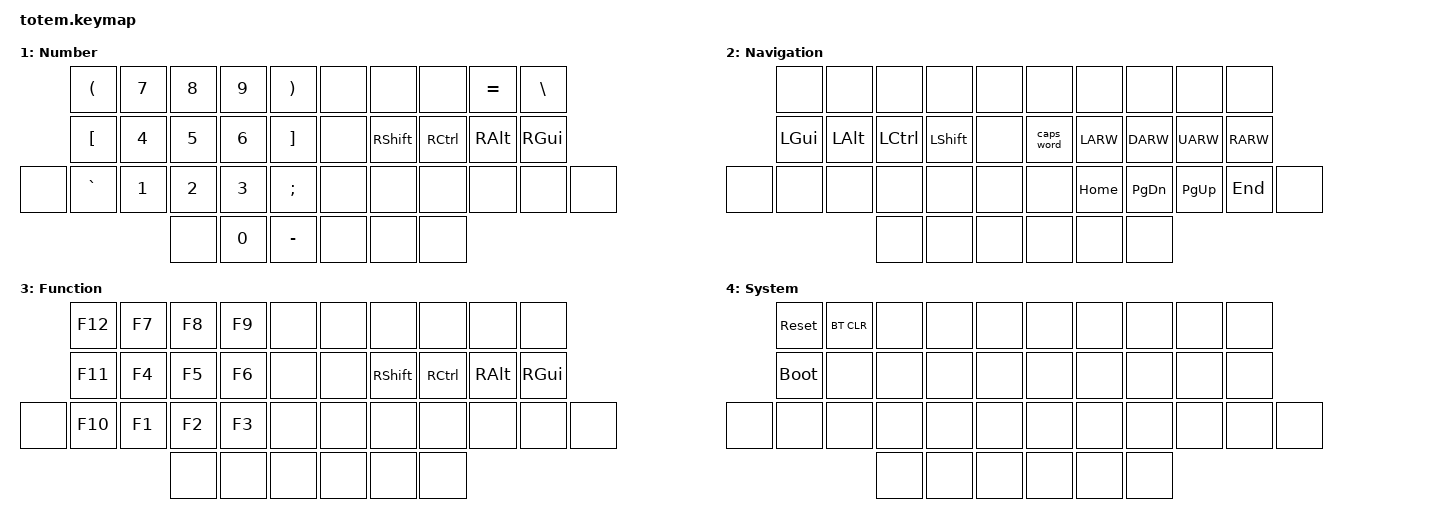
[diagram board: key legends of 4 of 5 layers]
//
//                                                        ▀▀▀▀▀     ▀▀▀▀▀          ▀▀█▀▀
//                                                        ▄▀▀▀▄  ▄  ▄▀▀▀▄  ▄  ▄▀▀▀▄  █  ▄▀▀▀▄
//                                                        █   █  █  █   █  █  █   █  █  █   █
//                                                         ▀▀▀   █   ▀▀▀   █   ▀▀▀   ▀   ▀▀▀
//                                                               █      ▄▄▄█▄▄▄    █   █  
//                                                               ▀      █  █  █     █▄█
//                                                             ▀▀▀▀▀    █  █  █      ▀
//                                                                      ▀  ▀  ▀
//
// ▄▄▄▄▄▄▄▄▄▄▄▄▄▄▄▄▄▄▄▄▄▄▄▄▄▄▄▄▄▄▄▄▄▄▄▄▄▄▄▄▄▄▄▄▄▄▄▄▄▄▄▄▄▄▄▄▄▄▄▄▄▄▄▄▄▄▄▄▄▄▄▄▄▄▄▄▄▄▄▄▄▄▄▄▄▄▄▄▄▄▄▄▄▄▄▄▄▄▄▄▄▄▄▄▄▄▄▄▄▄▄▄▄▄▄▄▄▄▄▄▄▄▄▄▄▄▄▄▄▄▄▄▄▄▄▄▄▄▄▄▄▄▄▄▄▄▄▄▄
       

#include <behaviors.dtsi>
#include <dt-bindings/zmk/keys.h>
#include <dt-bindings/zmk/bt.h>

#define BASE 0
#define NUM  1
#define NAV  2
#define FUNC 3
#define SYS  4

// Home row mods macro
#define GACS(k1,k2,k3,k4)   &hm LGUI k1     &hm LALT k2     &hm LCTRL k3    &hm LSHFT k4
#define SCAG(k1,k2,k3,k4)   &hm RSHFT k1    &hm RCTRL k2    &hm RALT k3     &hm RGUI k4

/ {
    behaviors {
        hm: homerow_mods {
            compatible = "zmk,behavior-hold-tap";
            label = "HOMEROW_MODS";
            #binding-cells = <2>;
            tapping-term-ms = <170>;
            quick-tap-ms = <0>;
            flavor = "tap-preferred";
            bindings = <&kp>, <&kp>;
        };
    };


    keymap {
        compatible = "zmk,keymap";
// ▄▄▄▄▄▄▄▄▄▄▄▄▄▄▄▄▄▄▄▄▄▄▄▄▄▄▄▄▄▄▄▄▄▄▄▄▄▄▄▄▄▄▄▄▄▄▄▄▄▄▄▄▄▄▄▄▄▄▄▄▄▄▄▄▄▄▄▄▄▄▄▄▄▄▄▄▄▄▄▄▄▄▄▄▄▄▄▄▄▄▄▄▄▄▄▄▄▄▄▄▄▄▄▄▄▄▄▄▄▄▄▄▄▄▄▄▄▄▄▄▄▄▄▄▄▄▄▄▄▄▄▄▄▄▄▄▄▄▄▄▄▄▄▄▄▄▄▄▄

        base_layer {
// ┏━━━━━━━━━━━━━━━━━━━━━━━━━━━━━━━━━━━━━━━┓
label= "BASE"                              ;
display-name= "Base"                       ;
// ┗━━━━━━━━━━━━━━━━━━━━━━━━━━━━━━━━━━━━━━━┛
//             ┏━━━━━━━━━━━┳━━━━━━━━━━━┳━━━━━━━━━━━┳━━━━━━━━━━━┳━━━━━━━━━━━┓   ┏━━━━━━━━━━━┳━━━━━━━━━━━┳━━━━━━━━━━━┳━━━━━━━━━━━┳━━━━━━━━━━━┓
//             ┃     Q     ┃     W     ┃     F     ┃     P     ┃     B     ┃   ┃     J     ┃     L     ┃     U     ┃     Y     ┃     '     ┃
//             ┣━━━━━━━━━━━╋━━━━━━━━━━━╋━━━━━━━━━━━╋━━━━━━━━━━━╋━━━━━━━━━━━┫   ┣━━━━━━━━━━━╋━━━━━━━━━━━╋━━━━━━━━━━━╋━━━━━━━━━━━╋━━━━━━━━━━━┫
//             ┃     A     ┃     R     ┃     S     ┃     T     ┃     G     ┃   ┃     M     ┃     N     ┃     E     ┃     I     ┃     O     ┃
// ┏━━━━━━━━━━━╋━━━━━━━━━━━╋━━━━━━━━━━━╋━━━━━━━━━━━╋━━━━━━━━━━━╋━━━━━━━━━━━┫   ┣━━━━━━━━━━━╋━━━━━━━━━━━╋━━━━━━━━━━━╋━━━━━━━━━━━╋━━━━━━━━━━━╋━━━━━━━━━━━┓
// ┃           ┃     Z     ┃     X     ┃     C     ┃     D     ┃     V     ┃   ┃     K     ┃     H     ┃     ,     ┃     .     ┃     /     ┃           ┃
// ┗━━━━━━━━━━━┻━━━━━━━━━━━┻━━━━━━━━━━━╋━━━━━━━━━━━╋━━━━━━━━━━━╋━━━━━━━━━━━┫   ┣━━━━━━━━━━━╋━━━━━━━━━━━╋━━━━━━━━━━━╋━━━━━━━━━━━┻━━━━━━━━━━━┻━━━━━━━━━━━┛
//                                     ┃    ESC    ┃    SPC    ┃    TAB    ┃   ┃   ENTER   ┃   BSPC    ┃    DEL    ┃
//                                     ┗━━━━━━━━━━━┻━━━━━━━━━━━┻━━━━━━━━━━━┛   ┗━━━━━━━━━━━┻━━━━━━━━━━━┻━━━━━━━━━━━┛
            bindings = <
// ╷           ╷           ╷           ╷           ╷           ╷           ╷   ╷           ╷           ╷           ╷           ╷           ╷           ╷

                &kp Q       &kp W       &kp F       &kp P       &kp B           &kp J       &kp L       &kp U       &kp Y       &kp SQT
                GACS(A,     R,          S,          T)          &kp G           &kp M       SCAG(N,     E,          I,          O)
    &kp Z       &kp Z       &kp X       &kp C       &kp D       &kp V           &kp K       &kp H       &kp COMMA   &kp DOT     &kp FSLH    &kp FSLH
                                        &kp ESC     &lt NAV SPACE &lt SYS TAB   &lt FUNC RET &lt NUM BSPC    &kp DEL
            >;
        };

// ▄▄▄▄▄▄▄▄▄▄▄▄▄▄▄▄▄▄▄▄▄▄▄▄▄▄▄▄▄▄▄▄▄▄▄▄▄▄▄▄▄▄▄▄▄▄▄▄▄▄▄▄▄▄▄▄▄▄▄▄▄▄▄▄▄▄▄▄▄▄▄▄▄▄▄▄▄▄▄▄▄▄▄▄▄▄▄▄▄▄▄▄▄▄▄▄▄▄▄▄▄▄▄▄▄▄▄▄▄▄▄▄▄▄▄▄▄▄▄▄▄▄▄▄▄▄▄▄▄▄▄▄▄▄▄▄▄▄▄▄▄▄▄▄▄▄▄▄▄


        number_layer {
// ┏━━━━━━━━━━━━━━━━━━━━━━━━━━━━━━━━━━━━━━━┓
label= "NUM"                               ;
display-name= "Number"                     ;
// ┗━━━━━━━━━━━━━━━━━━━━━━━━━━━━━━━━━━━━━━━┛
//             ┏━━━━━━━━━━━┳━━━━━━━━━━━┳━━━━━━━━━━━┳━━━━━━━━━━━┳━━━━━━━━━━━┓   ┏━━━━━━━━━━━┳━━━━━━━━━━━┳━━━━━━━━━━━┳━━━━━━━━━━━┳━━━━━━━━━━━┓
//             ┃     (     ┃     7     ┃     8     ┃     9     ┃     )     ┃   ┃           ┃           ┃           ┃     =     ┃     \     ┃
//             ┣━━━━━━━━━━━╋━━━━━━━━━━━╋━━━━━━━━━━━╋━━━━━━━━━━━╋━━━━━━━━━━━┫   ┣━━━━━━━━━━━╋━━━━━━━━━━━╋━━━━━━━━━━━╋━━━━━━━━━━━╋━━━━━━━━━━━┫
//             ┃     [     ┃     4     ┃     5     ┃     6     ┃     ]     ┃   ┃           ┃   RSHFT   ┃   RCTRL   ┃   RALT    ┃   RGUI    ┃
// ┏━━━━━━━━━━━╋━━━━━━━━━━━╋━━━━━━━━━━━╋━━━━━━━━━━━╋━━━━━━━━━━━╋━━━━━━━━━━━┫   ┣━━━━━━━━━━━╋━━━━━━━━━━━╋━━━━━━━━━━━╋━━━━━━━━━━━╋━━━━━━━━━━━╋━━━━━━━━━━━┓
// ┃           ┃     `     ┃     1     ┃     2     ┃     3     ┃     ;     ┃   ┃           ┃           ┃           ┃           ┃           ┃           ┃
// ┗━━━━━━━━━━━┻━━━━━━━━━━━┻━━━━━━━━━━━╋━━━━━━━━━━━╋━━━━━━━━━━━╋━━━━━━━━━━━┫   ┣━━━━━━━━━━━╋━━━━━━━━━━━╋━━━━━━━━━━━╋━━━━━━━━━━━┻━━━━━━━━━━━┻━━━━━━━━━━━┛
//                                     ┃           ┃     0     ┃     -     ┃   ┃           ┃           ┃           ┃
//                                     ┗━━━━━━━━━━━┻━━━━━━━━━━━┻━━━━━━━━━━━┛   ┗━━━━━━━━━━━┻━━━━━━━━━━━┻━━━━━━━━━━━┛
            bindings = <
// ╷           ╷           ╷           ╷           ╷           ╷           ╷   ╷           ╷           ╷           ╷           ╷           ╷           ╷

                &kp LPAR    &kp N7      &kp N8      &kp N9      &kp RPAR        &none       &none       &none       &kp EQUAL   &kp BSLH
                &kp LBKT    &kp N4      &kp N5      &kp N6      &kp RBKT        &none       &kp RSHFT   &kp RCTRL   &kp RALT    &kp RGUI
    &none       &kp GRAVE   &kp N1      &kp N2      &kp N3      &kp SEMI        &none       &none       &none       &none       &none       &none
                                        &none       &kp N0      &kp MINUS       &none       &none       &none
            >;
        };

// ▄▄▄▄▄▄▄▄▄▄▄▄▄▄▄▄▄▄▄▄▄▄▄▄▄▄▄▄▄▄▄▄▄▄▄▄▄▄▄▄▄▄▄▄▄▄▄▄▄▄▄▄▄▄▄▄▄▄▄▄▄▄▄▄▄▄▄▄▄▄▄▄▄▄▄▄▄▄▄▄▄▄▄▄▄▄▄▄▄▄▄▄▄▄▄▄▄▄▄▄▄▄▄▄▄▄▄▄▄▄▄▄▄▄▄▄▄▄▄▄▄▄▄▄▄▄▄▄▄▄▄▄▄▄▄▄▄▄▄▄▄▄▄▄▄▄▄▄▄


        navigation_layer {
// ┏━━━━━━━━━━━━━━━━━━━━━━━━━━━━━━━━━━━━━━━┓
label= "NAV"                               ;
display-name= "Navigation"                 ;
// ┗━━━━━━━━━━━━━━━━━━━━━━━━━━━━━━━━━━━━━━━┛
//             ┏━━━━━━━━━━━┳━━━━━━━━━━━┳━━━━━━━━━━━┳━━━━━━━━━━━┳━━━━━━━━━━━┓   ┏━━━━━━━━━━━┳━━━━━━━━━━━┳━━━━━━━━━━━┳━━━━━━━━━━━┳━━━━━━━━━━━┓
//             ┃           ┃           ┃           ┃           ┃           ┃   ┃           ┃           ┃           ┃           ┃           ┃
//             ┣━━━━━━━━━━━╋━━━━━━━━━━━╋━━━━━━━━━━━╋━━━━━━━━━━━╋━━━━━━━━━━━┫   ┣━━━━━━━━━━━╋━━━━━━━━━━━╋━━━━━━━━━━━╋━━━━━━━━━━━╋━━━━━━━━━━━┫
//             ┃   LGUI    ┃   LALT    ┃   LCTRL   ┃  LSHIFT   ┃           ┃   ┃ CAPS WORD ┃   LEFT    ┃   DOWN    ┃    UP     ┃   RIGHT   ┃
// ┏━━━━━━━━━━━╋━━━━━━━━━━━╋━━━━━━━━━━━╋━━━━━━━━━━━╋━━━━━━━━━━━╋━━━━━━━━━━━┫   ┣━━━━━━━━━━━╋━━━━━━━━━━━╋━━━━━━━━━━━╋━━━━━━━━━━━╋━━━━━━━━━━━╋━━━━━━━━━━━┓
// ┃           ┃           ┃           ┃           ┃           ┃           ┃   ┃           ┃   HOME    ┃  P DOWN   ┃   P UP    ┃    END    ┃           ┃
// ┗━━━━━━━━━━━┻━━━━━━━━━━━┻━━━━━━━━━━━╋━━━━━━━━━━━╋━━━━━━━━━━━╋━━━━━━━━━━━┫   ┣━━━━━━━━━━━╋━━━━━━━━━━━╋━━━━━━━━━━━╋━━━━━━━━━━━┻━━━━━━━━━━━┻━━━━━━━━━━━┛
//                                     ┃           ┃           ┃           ┃   ┃           ┃           ┃           ┃
//                                     ┗━━━━━━━━━━━┻━━━━━━━━━━━┻━━━━━━━━━━━┛   ┗━━━━━━━━━━━┻━━━━━━━━━━━┻━━━━━━━━━━━┛
            bindings = <
// ╷           ╷           ╷           ╷           ╷           ╷           ╷   ╷           ╷           ╷           ╷           ╷           ╷           ╷

                &none       &none       &none       &none       &none           &none       &none       &none       &none       &none
                &kp LGUI    &kp LALT    &kp LCTRL   &kp LSHIFT  &none           &caps_word  &kp LARW    &kp DARW    &kp UARW    &kp RARW
    &none       &none       &none       &none       &none       &none           &none       &kp HOME    &kp PG_DN   &kp PG_UP   &kp END     &none
                                        &none       &none       &none           &none       &none       &none
            >;
        };

// ▄▄▄▄▄▄▄▄▄▄▄▄▄▄▄▄▄▄▄▄▄▄▄▄▄▄▄▄▄▄▄▄▄▄▄▄▄▄▄▄▄▄▄▄▄▄▄▄▄▄▄▄▄▄▄▄▄▄▄▄▄▄▄▄▄▄▄▄▄▄▄▄▄▄▄▄▄▄▄▄▄▄▄▄▄▄▄▄▄▄▄▄▄▄▄▄▄▄▄▄▄▄▄▄▄▄▄▄▄▄▄▄▄▄▄▄▄▄▄▄▄▄▄▄▄▄▄▄▄▄▄▄▄▄▄▄▄▄▄▄▄▄▄▄▄▄▄▄▄


        function_layer {
// ┏━━━━━━━━━━━━━━━━━━━━━━━━━━━━━━━━━━━━━━━┓
label= "FUNC"                              ;
display-name= "Function"                   ;
// ┗━━━━━━━━━━━━━━━━━━━━━━━━━━━━━━━━━━━━━━━┛
//             ┏━━━━━━━━━━━┳━━━━━━━━━━━┳━━━━━━━━━━━┳━━━━━━━━━━━┳━━━━━━━━━━━┓   ┏━━━━━━━━━━━┳━━━━━━━━━━━┳━━━━━━━━━━━┳━━━━━━━━━━━┳━━━━━━━━━━━┓
//             ┃    F12    ┃    F7     ┃    F8     ┃    F9     ┃           ┃   ┃           ┃           ┃           ┃           ┃           ┃
//             ┣━━━━━━━━━━━╋━━━━━━━━━━━╋━━━━━━━━━━━╋━━━━━━━━━━━╋━━━━━━━━━━━┫   ┣━━━━━━━━━━━╋━━━━━━━━━━━╋━━━━━━━━━━━╋━━━━━━━━━━━╋━━━━━━━━━━━┫
//             ┃    F11    ┃    F4     ┃    F5     ┃    F6     ┃           ┃   ┃           ┃   RSHFT   ┃   RCTRL   ┃   RALT    ┃   RGUI    ┃
// ┏━━━━━━━━━━━╋━━━━━━━━━━━╋━━━━━━━━━━━╋━━━━━━━━━━━╋━━━━━━━━━━━╋━━━━━━━━━━━┫   ┣━━━━━━━━━━━╋━━━━━━━━━━━╋━━━━━━━━━━━╋━━━━━━━━━━━╋━━━━━━━━━━━╋━━━━━━━━━━━┓
// ┃           ┃    F10    ┃    F1     ┃    F2     ┃    F3     ┃           ┃   ┃           ┃           ┃           ┃           ┃           ┃           ┃
// ┗━━━━━━━━━━━┻━━━━━━━━━━━┻━━━━━━━━━━━╋━━━━━━━━━━━╋━━━━━━━━━━━╋━━━━━━━━━━━┫   ┣━━━━━━━━━━━╋━━━━━━━━━━━╋━━━━━━━━━━━╋━━━━━━━━━━━┻━━━━━━━━━━━┻━━━━━━━━━━━┛
//                                     ┃           ┃           ┃           ┃   ┃           ┃           ┃           ┃
//                                     ┗━━━━━━━━━━━┻━━━━━━━━━━━┻━━━━━━━━━━━┛   ┗━━━━━━━━━━━┻━━━━━━━━━━━┻━━━━━━━━━━━┛
            bindings = <
// ╷           ╷           ╷           ╷           ╷           ╷           ╷   ╷           ╷           ╷           ╷           ╷           ╷           ╷

                &kp F12     &kp F7      &kp F8      &kp F9      &none           &none       &none       &none       &none       &none
                &kp F11     &kp F4      &kp F5      &kp F6      &none           &none       &kp RSHFT   &kp RCTRL   &kp RALT    &kp RGUI
    &none       &kp F10     &kp F1      &kp F2      &kp F3      &none           &none       &none       &none       &none       &none       &none
                                        &none       &none       &none           &none       &none       &none
            >;
        };

// ▄▄▄▄▄▄▄▄▄▄▄▄▄▄▄▄▄▄▄▄▄▄▄▄▄▄▄▄▄▄▄▄▄▄▄▄▄▄▄▄▄▄▄▄▄▄▄▄▄▄▄▄▄▄▄▄▄▄▄▄▄▄▄▄▄▄▄▄▄▄▄▄▄▄▄▄▄▄▄▄▄▄▄▄▄▄▄▄▄▄▄▄▄▄▄▄▄▄▄▄▄▄▄▄▄▄▄▄▄▄▄▄▄▄▄▄▄▄▄▄▄▄▄▄▄▄▄▄▄▄▄▄▄▄▄▄▄▄▄▄▄▄▄▄▄▄▄▄▄


        system_layer {
// ┏━━━━━━━━━━━━━━━━━━━━━━━━━━━━━━━━━━━━━━━┓
label= "SYS"                               ;
display-name= "System"                     ;
// ┗━━━━━━━━━━━━━━━━━━━━━━━━━━━━━━━━━━━━━━━┛
//             ┏━━━━━━━━━━━┳━━━━━━━━━━━┳━━━━━━━━━━━┳━━━━━━━━━━━┳━━━━━━━━━━━┓   ┏━━━━━━━━━━━┳━━━━━━━━━━━┳━━━━━━━━━━━┳━━━━━━━━━━━┳━━━━━━━━━━━┓
//             ┃   RESET   ┃ BT CLEAR  ┃           ┃           ┃           ┃   ┃           ┃           ┃           ┃           ┃           ┃
//             ┣━━━━━━━━━━━╋━━━━━━━━━━━╋━━━━━━━━━━━╋━━━━━━━━━━━╋━━━━━━━━━━━┫   ┣━━━━━━━━━━━╋━━━━━━━━━━━╋━━━━━━━━━━━╋━━━━━━━━━━━╋━━━━━━━━━━━┫
//             ┃ BOOTLOAD  ┃           ┃           ┃           ┃           ┃   ┃           ┃           ┃           ┃           ┃           ┃
// ┏━━━━━━━━━━━╋━━━━━━━━━━━╋━━━━━━━━━━━╋━━━━━━━━━━━╋━━━━━━━━━━━╋━━━━━━━━━━━┫   ┣━━━━━━━━━━━╋━━━━━━━━━━━╋━━━━━━━━━━━╋━━━━━━━━━━━╋━━━━━━━━━━━╋━━━━━━━━━━━┓
// ┃           ┃           ┃           ┃           ┃           ┃           ┃   ┃           ┃           ┃           ┃           ┃           ┃           ┃
// ┗━━━━━━━━━━━┻━━━━━━━━━━━┻━━━━━━━━━━━╋━━━━━━━━━━━╋━━━━━━━━━━━╋━━━━━━━━━━━┫   ┣━━━━━━━━━━━╋━━━━━━━━━━━╋━━━━━━━━━━━╋━━━━━━━━━━━┻━━━━━━━━━━━┻━━━━━━━━━━━┛
//                                     ┃           ┃           ┃           ┃   ┃           ┃           ┃           ┃
//                                     ┗━━━━━━━━━━━┻━━━━━━━━━━━┻━━━━━━━━━━━┛   ┗━━━━━━━━━━━┻━━━━━━━━━━━┻━━━━━━━━━━━┛
            bindings = <
// ╷           ╷           ╷           ╷           ╷           ╷           ╷   ╷           ╷           ╷           ╷           ╷           ╷           ╷

                &sys_reset  &bt BT_CLR  &none       &none       &none           &none       &none       &none       &none       &none
                &bootloader &none       &none       &none       &none           &none       &none       &none       &none       &none
    &none       &none       &none       &none       &none       &none           &none       &none       &none       &none       &none       &none
                                        &none       &none       &none           &none       &none       &none
            >;
        };
    };
};
